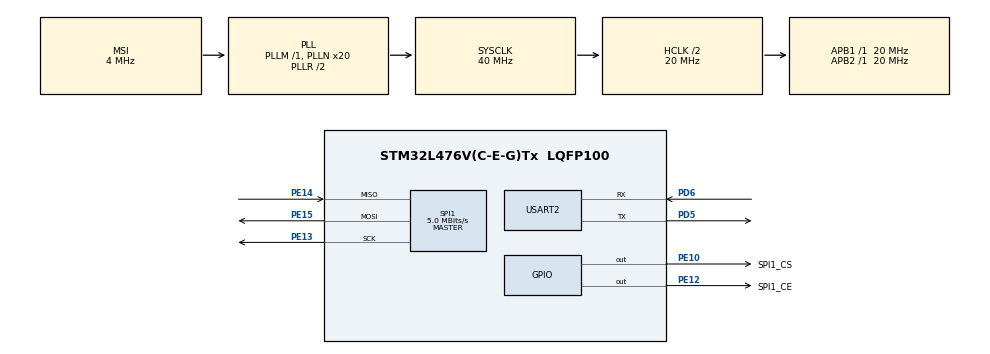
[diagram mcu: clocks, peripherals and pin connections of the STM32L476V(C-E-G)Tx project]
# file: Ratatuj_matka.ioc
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Mcu.Family=STM32L4
Mcu.Name=STM32L476V(C-E-G)Tx
Mcu.Package=LQFP100
NVIC.PriorityGroup=NVIC_PRIORITYGROUP_4
PD5.Mode=Asynchronous
PD5.Signal=USART2_TX
PD6.Mode=Asynchronous
PD6.Signal=USART2_RX
PE10.GPIO_Label=SPI1_CS
PE10.Signal=GPIO_Output
PE12.GPIO_Label=SPI1_CE
PE12.Signal=GPIO_Output
PE13.Mode=Full_Duplex_Master
PE13.Signal=SPI1_SCK
PE14.Mode=Full_Duplex_Master
PE14.Signal=SPI1_MISO
PE15.Mode=Full_Duplex_Master
PE15.Signal=SPI1_MOSI
ProjectManager.HeapSize=0x200
ProjectManager.StackSize=0x400
ProjectManager.TargetToolchain=TrueSTUDIO
RCC.ADCFreq_Value=48000000
RCC.AHBCLKDivider=RCC_SYSCLK_DIV2
RCC.AHBFreq_Value=20000000
RCC.APB1Freq_Value=20000000
RCC.APB1TimFreq_Value=20000000
RCC.APB2Freq_Value=20000000
RCC.APB2TimFreq_Value=20000000
RCC.CortexFreq_Value=20000000
RCC.HCLKFreq_Value=20000000
RCC.HSE_VALUE=8000000
RCC.HSI_VALUE=16000000
RCC.LSE_VALUE=32768
RCC.MSI_VALUE=4000000
RCC.PLLN=20
RCC.PLLSAI1N=24
RCC.PREFETCH_ENABLE=1
RCC.SYSCLKFreq_VALUE=40000000
RCC.SYSCLKSource=RCC_SYSCLKSOURCE_PLLCLK
RCC.USBFreq_Value=48000000
RCC.VCOOutputFreq_Value=80000000
SPI1.BaudRatePrescaler=SPI_BAUDRATEPRESCALER_4
SPI1.CalculateBaudRate=5.0 MBits/s
SPI1.DataSize=SPI_DATASIZE_8BIT
SPI1.Direction=SPI_DIRECTION_2LINES
SPI1.Mode=SPI_MODE_MASTER
SPI1.VirtualType=VM_MASTER
USART2.VirtualMode-Asynchronous=VM_ASYNC
USART2.WordLength=WORDLENGTH_8B
board=32L476GDISCOVERY

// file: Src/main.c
/**
  ******************************************************************************
  * @file           : main.c
  * @brief          : Main program body
  ******************************************************************************
  ** This notice applies to any and all portions of this file
  * that are not between comment pairs USER CODE BEGIN and
  * USER CODE END. Other portions of this file, whether
  * inserted by the user or by software development tools
  * are owned by their respective copyright owners.
  *
  * COPYRIGHT(c) 2018 STMicroelectronics
  *
  * Redistribution and use in source and binary forms, with or without modification,
  * are permitted provided that the following conditions are met:
  *   1. Redistributions of source code must retain the above copyright notice,
  *      this list of conditions and the following disclaimer.
  *   2. Redistributions in binary form must reproduce the above copyright notice,
  *      this list of conditions and the following disclaimer in the documentation
  *      and/or other materials provided with the distribution.
  *   3. Neither the name of STMicroelectronics nor the names of its contributors
  *      may be used to endorse or promote products derived from this software
  *      without specific prior written permission.
  *
  * THIS SOFTWARE IS PROVIDED BY THE COPYRIGHT HOLDERS AND CONTRIBUTORS "AS IS"
  * AND ANY EXPRESS OR IMPLIED WARRANTIES, INCLUDING, BUT NOT LIMITED TO, THE
  * IMPLIED WARRANTIES OF MERCHANTABILITY AND FITNESS FOR A PARTICULAR PURPOSE ARE
  * DISCLAIMED. IN NO EVENT SHALL THE COPYRIGHT HOLDER OR CONTRIBUTORS BE LIABLE
  * FOR ANY DIRECT, INDIRECT, INCIDENTAL, SPECIAL, EXEMPLARY, OR CONSEQUENTIAL
  * DAMAGES (INCLUDING, BUT NOT LIMITED TO, PROCUREMENT OF SUBSTITUTE GOODS OR
  * SERVICES; LOSS OF USE, DATA, OR PROFITS; OR BUSINESS INTERRUPTION) HOWEVER
  * CAUSED AND ON ANY THEORY OF LIABILITY, WHETHER IN CONTRACT, STRICT LIABILITY,
  * OR TORT (INCLUDING NEGLIGENCE OR OTHERWISE) ARISING IN ANY WAY OUT OF THE USE
  * OF THIS SOFTWARE, EVEN IF ADVISED OF THE POSSIBILITY OF SUCH DAMAGE.
  *
  ******************************************************************************
  */
#include "main.h"
#include "stm32l4xx_hal.h"
#include "spi.h"
#include "usart.h"
#include "gpio.h"

/* USER CODE BEGIN Includes */
#include "main_module_radio.h"
/* USER CODE END Includes */

/* USER CODE BEGIN PV */
/* Private variables ---------------------------------------------------------*/
uint8_t dataIn[32];
TM_NRF24L01_Transmit_Status_t transmissionStatus;
/* USER CODE END PV */

void SystemClock_Config(void);

/* USER CODE BEGIN PFP */
/* Private function prototypes -----------------------------------------------*/
int _write(int file, char *ptr, int len){
	HAL_UART_Transmit(&huart2,(uint8_t *)ptr, len, 50);
	return len;
}

/* USER CODE END PFP */

int main(void)
{

  /* MCU Configuration----------------------------------------------------------*/

  /* Reset of all peripherals, Initializes the Flash interface and the Systick. */
  HAL_Init();

  /* Configure the system clock */
  SystemClock_Config();

  /* Initialize all configured peripherals */
  MX_GPIO_Init();
  MX_SPI1_Init();
  MX_USART2_UART_Init();
  /* USER CODE BEGIN 2 */
  HAL_GPIO_WritePin(SPI1_CS_GPIO_Port,SPI1_CS_Pin,GPIO_PIN_SET);
  HAL_Delay(100);
//while(1)
//{
//	printf("%d\r\n",TM_NRF24L01_ReadRegister(0x07));
//}
mainModuleRadioInit();
  /* USER CODE END 2 */

  /* Infinite loop */
  /* USER CODE BEGIN WHILE */
  while (1)
  {/* If data is ready on NRF24L01+ */
	//  printf("Ala ma kota\r\n");
	  		if (TM_NRF24L01_DataReady()) {
	  			/* Get data from NRF24L01+ */
	  			TM_NRF24L01_GetData(dataIn);
	  			printf("data: %s\r\n", dataIn);
	  			/* Send it back, automatically goes to TX mode */
	  			//TM_NRF24L01_Transmit(dataIn);

	  			/* Wait for data to be sent */
	  			//do {
	  			//	transmissionStatus = TM_NRF24L01_GetTransmissionStatus();
	  			//} while (transmissionStatus == TM_NRF24L01_Transmit_Status_Sending);

	  			/* Go back to RX Mode */
	  			TM_NRF24L01_PowerUpRx();
	  		}

  /* USER CODE END WHILE */

  }

}

void SystemClock_Config(void)
{

  RCC_OscInitTypeDef RCC_OscInitStruct;
  RCC_ClkInitTypeDef RCC_ClkInitStruct;
  RCC_PeriphCLKInitTypeDef PeriphClkInit;

    /**Initializes the CPU, AHB and APB busses clocks
    */
  RCC_OscInitStruct.OscillatorType = RCC_OSCILLATORTYPE_MSI;
  RCC_OscInitStruct.MSIState = RCC_MSI_ON;
  RCC_OscInitStruct.MSICalibrationValue = 0;
  RCC_OscInitStruct.MSIClockRange = RCC_MSIRANGE_6;
  RCC_OscInitStruct.PLL.PLLState = RCC_PLL_ON;
  RCC_OscInitStruct.PLL.PLLSource = RCC_PLLSOURCE_MSI;
  RCC_OscInitStruct.PLL.PLLM = 1;
  RCC_OscInitStruct.PLL.PLLN = 20;
  RCC_OscInitStruct.PLL.PLLP = RCC_PLLP_DIV7;
  RCC_OscInitStruct.PLL.PLLQ = RCC_PLLQ_DIV2;
  RCC_OscInitStruct.PLL.PLLR = RCC_PLLR_DIV2;
  if (HAL_RCC_OscConfig(&RCC_OscInitStruct) != HAL_OK)
  {
    _Error_Handler(__FILE__, __LINE__);
  }

    /**Initializes the CPU, AHB and APB busses clocks
    */
  RCC_ClkInitStruct.ClockType = RCC_CLOCKTYPE_HCLK|RCC_CLOCKTYPE_SYSCLK
                              |RCC_CLOCKTYPE_PCLK1|RCC_CLOCKTYPE_PCLK2;
  RCC_ClkInitStruct.SYSCLKSource = RCC_SYSCLKSOURCE_PLLCLK;
  RCC_ClkInitStruct.AHBCLKDivider = RCC_SYSCLK_DIV2;
  RCC_ClkInitStruct.APB1CLKDivider = RCC_HCLK_DIV1;
  RCC_ClkInitStruct.APB2CLKDivider = RCC_HCLK_DIV1;

  if (HAL_RCC_ClockConfig(&RCC_ClkInitStruct, FLASH_LATENCY_1) != HAL_OK)
  {
    _Error_Handler(__FILE__, __LINE__);
  }

  PeriphClkInit.PeriphClockSelection = RCC_PERIPHCLK_USART2;
  PeriphClkInit.Usart2ClockSelection = RCC_USART2CLKSOURCE_PCLK1;
  if (HAL_RCCEx_PeriphCLKConfig(&PeriphClkInit) != HAL_OK)
  {
    _Error_Handler(__FILE__, __LINE__);
  }

    /**Configure the main internal regulator output voltage
    */
  if (HAL_PWREx_ControlVoltageScaling(PWR_REGULATOR_VOLTAGE_SCALE1) != HAL_OK)
  {
    _Error_Handler(__FILE__, __LINE__);
  }

    /**Configure the Systick interrupt time
    */
  HAL_SYSTICK_Config(HAL_RCC_GetHCLKFreq()/1000);

    /**Configure the Systick
    */
  HAL_SYSTICK_CLKSourceConfig(SYSTICK_CLKSOURCE_HCLK);

  /* SysTick_IRQn interrupt configuration */
  HAL_NVIC_SetPriority(SysTick_IRQn, 0, 0);
}

void _Error_Handler(char *file, int line)
{
  while(1)
  {
  }
}

/************************ (C) COPYRIGHT STMicroelectronics *****END OF FILE****/
